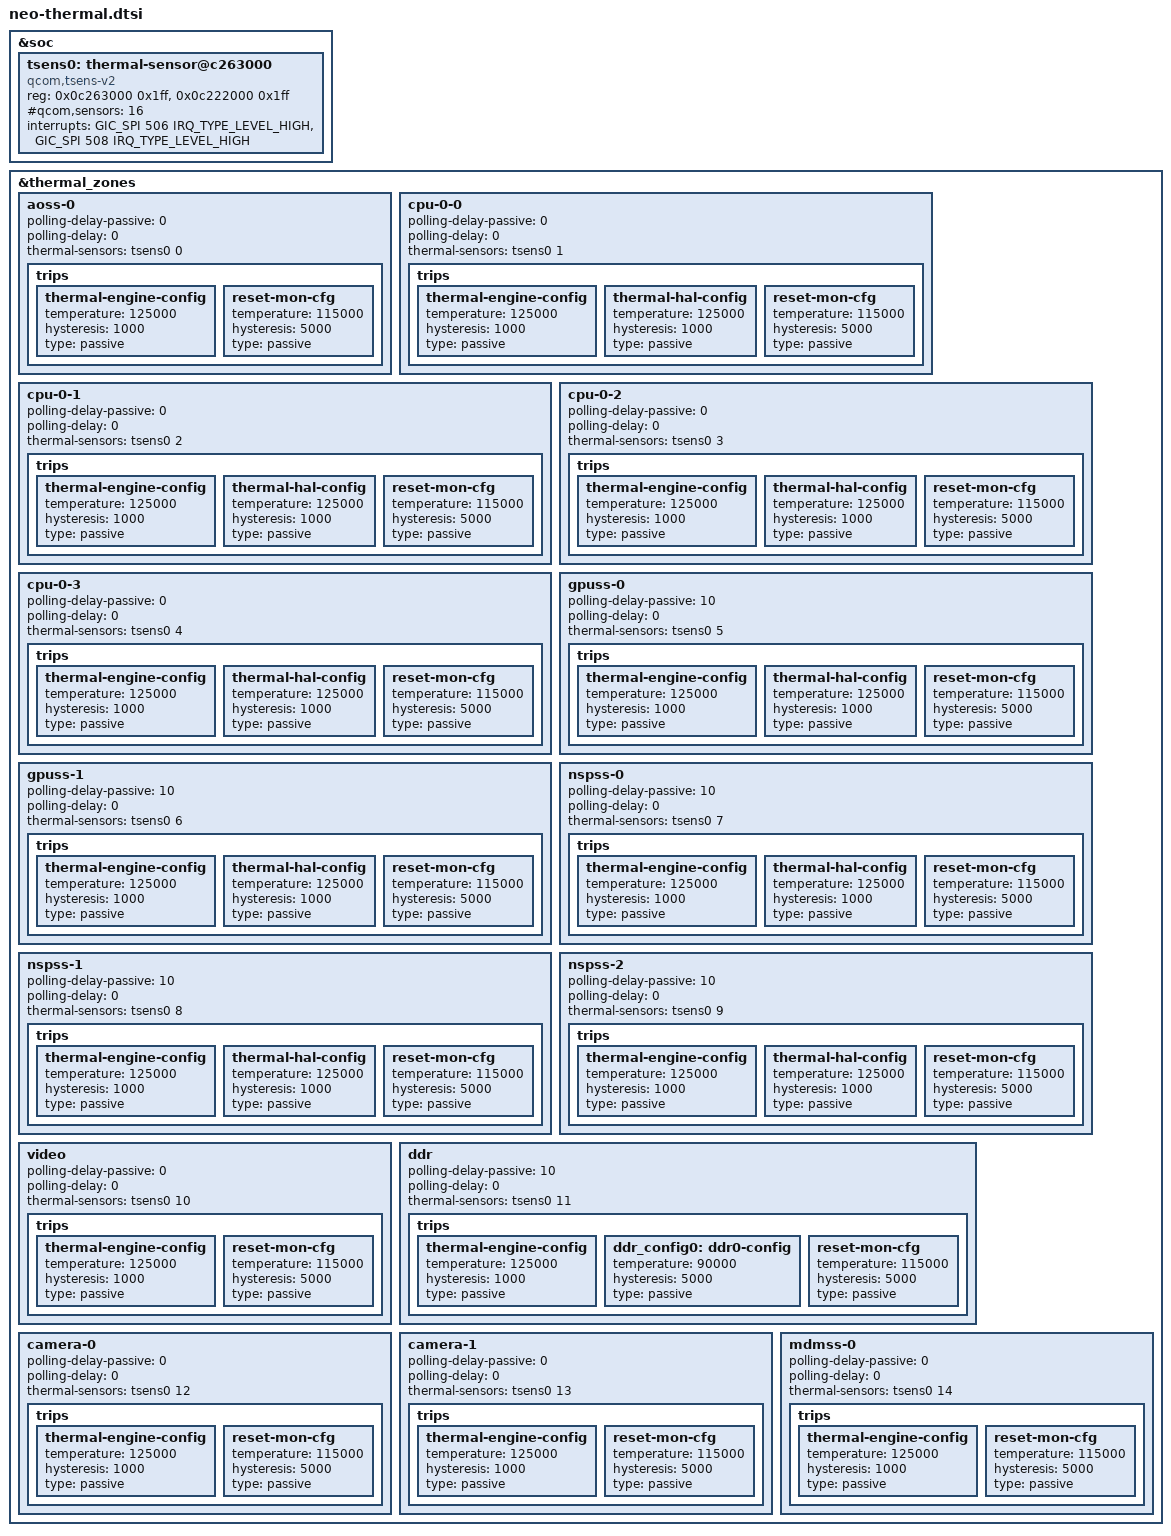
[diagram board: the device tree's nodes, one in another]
#include <dt-bindings/thermal/thermal_qti.h>

&soc {
	tsens0: thermal-sensor@c263000 {
		compatible = "qcom,tsens-v2";
		reg = <0x0c263000 0x1ff>, /* TM */
			<0x0c222000 0x1ff>; /* SROT */
		#qcom,sensors = <16>;
		interrupts = <GIC_SPI 506 IRQ_TYPE_LEVEL_HIGH>,
			     <GIC_SPI 508 IRQ_TYPE_LEVEL_HIGH>;
		interrupt-names = "uplow","critical";
		#thermal-sensor-cells = <1>;
	};
};

&thermal_zones {
	aoss-0 {
		polling-delay-passive = <0>;
		polling-delay = <0>;
		thermal-sensors = <&tsens0 0>;
		trips {
			thermal-engine-config {
				temperature = <125000>;
				hysteresis = <1000>;
				type = "passive";
			};

			reset-mon-cfg {
				temperature = <115000>;
				hysteresis = <5000>;
				type = "passive";
			};
		};
	};

	cpu-0-0 {
		polling-delay-passive = <0>;
		polling-delay = <0>;
		thermal-sensors = <&tsens0 1>;
		trips {
			thermal-engine-config {
				temperature = <125000>;
				hysteresis = <1000>;
				type = "passive";
			};

			thermal-hal-config {
				temperature = <125000>;
				hysteresis = <1000>;
				type = "passive";
			};

			reset-mon-cfg {
				temperature = <115000>;
				hysteresis = <5000>;
				type = "passive";
			};
		};
	};

	cpu-0-1 {
		polling-delay-passive = <0>;
		polling-delay = <0>;
		thermal-sensors = <&tsens0 2>;
		trips {
			thermal-engine-config {
				temperature = <125000>;
				hysteresis = <1000>;
				type = "passive";
			};

			thermal-hal-config {
				temperature = <125000>;
				hysteresis = <1000>;
				type = "passive";
			};

			reset-mon-cfg {
				temperature = <115000>;
				hysteresis = <5000>;
				type = "passive";
			};
		};
	};

	cpu-0-2 {
		polling-delay-passive = <0>;
		polling-delay = <0>;
		thermal-sensors = <&tsens0 3>;
		trips {
			thermal-engine-config {
				temperature = <125000>;
				hysteresis = <1000>;
				type = "passive";
			};

			thermal-hal-config {
				temperature = <125000>;
				hysteresis = <1000>;
				type = "passive";
			};

			reset-mon-cfg {
				temperature = <115000>;
				hysteresis = <5000>;
				type = "passive";
			};
		};
	};

	cpu-0-3 {
		polling-delay-passive = <0>;
		polling-delay = <0>;
		thermal-sensors = <&tsens0 4>;
		trips {
			thermal-engine-config {
				temperature = <125000>;
				hysteresis = <1000>;
				type = "passive";
			};

			thermal-hal-config {
				temperature = <125000>;
				hysteresis = <1000>;
				type = "passive";
			};

			reset-mon-cfg {
				temperature = <115000>;
				hysteresis = <5000>;
				type = "passive";
			};
		};
	};

	gpuss-0 {
		polling-delay-passive = <10>;
		polling-delay = <0>;
		thermal-sensors = <&tsens0 5>;
		trips {
			thermal-engine-config {
				temperature = <125000>;
				hysteresis = <1000>;
				type = "passive";
			};

			thermal-hal-config {
				temperature = <125000>;
				hysteresis = <1000>;
				type = "passive";
			};

			reset-mon-cfg {
				temperature = <115000>;
				hysteresis = <5000>;
				type = "passive";
			};
		};
	};

	gpuss-1 {
		polling-delay-passive = <10>;
		polling-delay = <0>;
		thermal-sensors = <&tsens0 6>;
		trips {
			thermal-engine-config {
				temperature = <125000>;
				hysteresis = <1000>;
				type = "passive";
			};

			thermal-hal-config {
				temperature = <125000>;
				hysteresis = <1000>;
				type = "passive";
			};

			reset-mon-cfg {
				temperature = <115000>;
				hysteresis = <5000>;
				type = "passive";
			};
		};
	};

	nspss-0 {
		polling-delay-passive = <10>;
		polling-delay = <0>;
		thermal-sensors = <&tsens0 7>;
		trips {
			thermal-engine-config {
				temperature = <125000>;
				hysteresis = <1000>;
				type = "passive";
			};

			thermal-hal-config {
				temperature = <125000>;
				hysteresis = <1000>;
				type = "passive";
			};

			reset-mon-cfg {
				temperature = <115000>;
				hysteresis = <5000>;
				type = "passive";
			};
		};
	};

	nspss-1 {
		polling-delay-passive = <10>;
		polling-delay = <0>;
		thermal-sensors = <&tsens0 8>;
		trips {
			thermal-engine-config {
				temperature = <125000>;
				hysteresis = <1000>;
				type = "passive";
			};

			thermal-hal-config {
				temperature = <125000>;
				hysteresis = <1000>;
				type = "passive";
			};

			reset-mon-cfg {
				temperature = <115000>;
				hysteresis = <5000>;
				type = "passive";
			};
		};
	};

	nspss-2 {
		polling-delay-passive = <10>;
		polling-delay = <0>;
		thermal-sensors = <&tsens0 9>;
		trips {
			thermal-engine-config {
				temperature = <125000>;
				hysteresis = <1000>;
				type = "passive";
			};

			thermal-hal-config {
				temperature = <125000>;
				hysteresis = <1000>;
				type = "passive";
			};

			reset-mon-cfg {
				temperature = <115000>;
				hysteresis = <5000>;
				type = "passive";
			};
		};
	};

	video {
		polling-delay-passive = <0>;
		polling-delay = <0>;
		thermal-sensors = <&tsens0 10>;
		trips {
			thermal-engine-config {
				temperature = <125000>;
				hysteresis = <1000>;
				type = "passive";
			};

			reset-mon-cfg {
				temperature = <115000>;
				hysteresis = <5000>;
				type = "passive";
			};
		};
	};

	ddr {
		polling-delay-passive = <10>;
		polling-delay = <0>;
		thermal-sensors = <&tsens0 11>;
		trips {
			thermal-engine-config {
				temperature = <125000>;
				hysteresis = <1000>;
				type = "passive";
			};

			ddr_config0: ddr0-config {
				temperature = <90000>;
				hysteresis = <5000>;
				type = "passive";
			};

			reset-mon-cfg {
				temperature = <115000>;
				hysteresis = <5000>;
				type = "passive";
			};
		};
	};

	camera-0 {
		polling-delay-passive = <0>;
		polling-delay = <0>;
		thermal-sensors = <&tsens0 12>;
		trips {
			thermal-engine-config {
				temperature = <125000>;
				hysteresis = <1000>;
				type = "passive";
			};

			reset-mon-cfg {
				temperature = <115000>;
				hysteresis = <5000>;
				type = "passive";
			};
		};
	};

	camera-1 {
		polling-delay-passive = <0>;
		polling-delay = <0>;
		thermal-sensors = <&tsens0 13>;
		trips {
			thermal-engine-config {
				temperature = <125000>;
				hysteresis = <1000>;
				type = "passive";
			};

			reset-mon-cfg {
				temperature = <115000>;
				hysteresis = <5000>;
				type = "passive";
			};
		};
	};

	mdmss-0 {
		polling-delay-passive = <0>;
		polling-delay = <0>;
		thermal-sensors = <&tsens0 14>;
		trips {
			thermal-engine-config {
				temperature = <125000>;
				hysteresis = <1000>;
				type = "passive";
			};

			reset-mon-cfg {
				temperature = <115000>;
				hysteresis = <5000>;
				type = "passive";
			};
		};
	};
};
